# npck3m7k register map
Registers are 8-bit, read-write, no defined reset value unless marked. A register's access mark holds for its fields unless they carry their own. Offsets are from the block's base; [hi:lo] are bit positions; {n}, {i} and the like mark numbered series.

## PM4 — PM4 Module
Base 0x400CF000
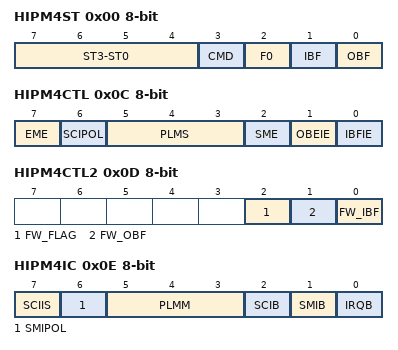
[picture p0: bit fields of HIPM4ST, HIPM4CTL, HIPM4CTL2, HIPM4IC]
0x00 HIPM4ST
  [7:4] ST3-ST0, [3] CMD, [2] F0, [1] IBF, [0] OBF
0x02 HIPM4DO
0x04 HIPM4DI
0x05 SHIPM4DI
0x06 HIPM4DOC
0x08 HIPM4DOM
0x0A HIPM4DIC
0x0C HIPM4CTL
  [7] EME, [6] SCIPOL, [5:3] PLMS, [2] SME, [1] OBEIE, [0] IBFIE
0x0D HIPM4CTL2
  [2] FW_FLAG, [1] FW_OBF, [0] FW_IBF
0x0E HIPM4IC
  [7] SCIIS, [6] SMIPOL, [5:3] PLMM, [2] SCIB, [1] SMIB, [0] IRQB
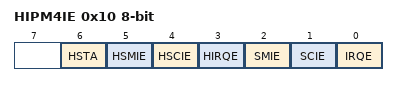
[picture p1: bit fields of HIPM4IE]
0x10 HIPM4IE
  [6] HSTA, [5] HSMIE, [4] HSCIE, [3] HIRQE, [2] SMIE, [1] SCIE, [0] IRQE
0x11 PM4_VER

## SHM — SHM Module
Base 0x40010000
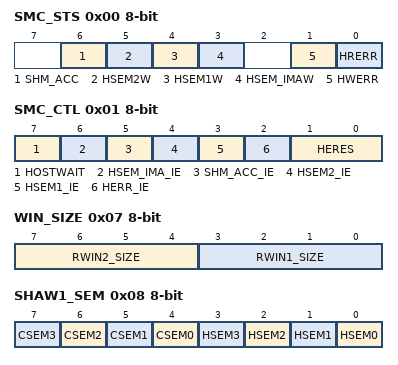
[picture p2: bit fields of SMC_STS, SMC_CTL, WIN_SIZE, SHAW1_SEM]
0x00 SMC_STS
  [6] SHM_ACC, [5] HSEM2W, [4] HSEM1W, [3] HSEM_IMAW, [1] HWERR, [0] HRERR
0x01 SMC_CTL
  [7] HOSTWAIT, [6] HSEM_IMA_IE, [5] SHM_ACC_IE, [4] HSEM2_IE, [3] HSEM1_IE, [2] HERR_IE, [1:0] HERES
0x02 SHM_CTL
  [6] STALL_HOST
0x05 IMA_WIN_SIZE
  [3:0] IMA_SIZE
0x07 WIN_SIZE
  [7:4] RWIN2_SIZE, [3:0] RWIN1_SIZE
0x08 SHAW1_SEM
  [n+4] CSEM{n} (n=0..3), [n] HSEM{n} (n=0..3)
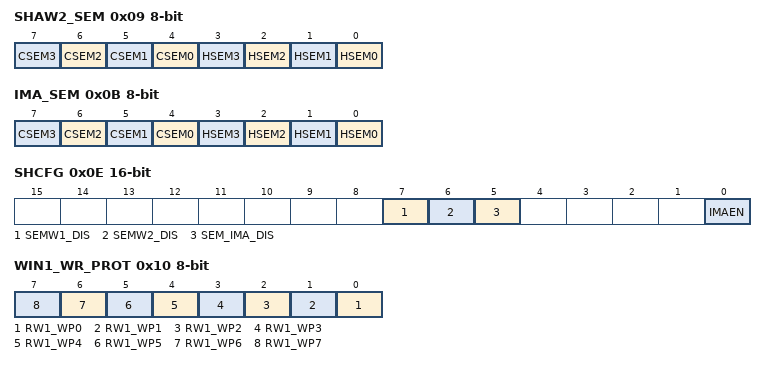
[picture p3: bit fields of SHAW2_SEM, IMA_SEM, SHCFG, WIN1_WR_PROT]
0x09 SHAW2_SEM
  [n+4] CSEM{n} (n=0..3), [n] HSEM{n} (n=0..3)
0x0B IMA_SEM
  [n+4] CSEM{n} (n=0..3), [n] HSEM{n} (n=0..3)
0x0E SHCFG 16-bit
  [7] SEMW1_DIS, [6] SEMW2_DIS, [5] SEM_IMA_DIS, [0] IMAEN
0x10 WIN1_WR_PROT
  [n] RW1_WP{n} (n=0..7)
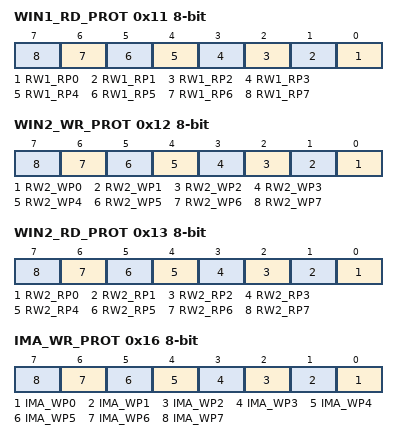
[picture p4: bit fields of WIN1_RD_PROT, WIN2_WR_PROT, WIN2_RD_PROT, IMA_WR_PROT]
0x11 WIN1_RD_PROT
  [n] RW1_RP{n} (n=0..7)
0x12 WIN2_WR_PROT
  [n] RW2_WP{n} (n=0..7)
0x13 WIN2_RD_PROT
  [n] RW2_RP{n} (n=0..7)
0x16 IMA_WR_PROT
  [n] IMA_WP{n} (n=0..7)
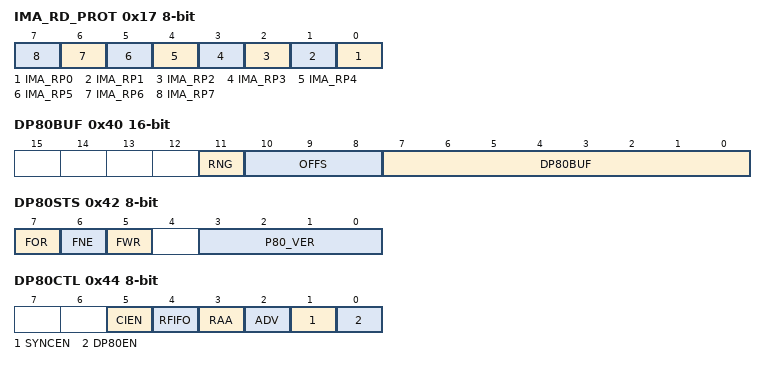
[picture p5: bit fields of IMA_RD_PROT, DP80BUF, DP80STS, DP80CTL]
0x17 IMA_RD_PROT
  [n] IMA_RP{n} (n=0..7)
0x20 WIN_BASE1 32-bit
0x24 WIN_BASE2 32-bit
0x2C IMA_BASE 32-bit
0x3A RST_CFG
  [7] LRESET_PLTRST_DIS
0x40 DP80BUF 16-bit
  [11] RNG, [10:8] OFFS, [7:0] DP80BUF
0x42 DP80STS
  [7] FOR, [6] FNE, [5] FWR, [3:0] P80_VER
0x44 DP80CTL
  [5] CIEN, [4] RFIFO, [3] RAA, [2] ADV, [1] SYNCEN, [0] DP80EN
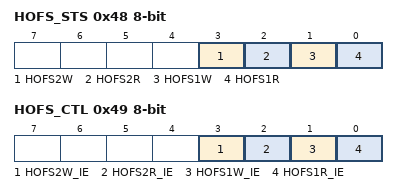
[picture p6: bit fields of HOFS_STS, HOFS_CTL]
0x48 HOFS_STS
  [3] HOFS2W, [2] HOFS2R, [1] HOFS1W, [0] HOFS1R
0x49 HOFS_CTL
  [3] HOFS2W_IE, [2] HOFS2R_IE, [1] HOFS1W_IE, [0] HOFS1R_IE
0x4A COFS2 16-bit
  [11:0] COFS2_DAT
0x4C COFS1 16-bit
  [11:0] COFS1_DAT
0x50 IHOFS2 16-bit
  [11:0] HOFS2_DAT
0x52 IHOFS1 16-bit
  [11:0] HOFS1_DAT
0x7F VERSION

## MSWC — MSWC Module
Base 0x400C1000
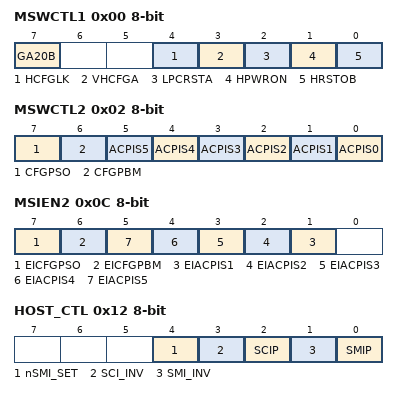
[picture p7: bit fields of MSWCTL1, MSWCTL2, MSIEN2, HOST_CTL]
0x00 MSWCTL1
  [7] GA20B, [4] HCFGLK, [3] VHCFGA, [2] LPCRSTA, [1] HPWRON, [0] HRSTOB
0x02 MSWCTL2
  [7] CFGPSO, [6] CFGPBM, [n] ACPIS{n} (n=0..5)
0x08 HCBAL
  [7:0] HCBA7-0
0x0A HCBAH
  [7:0] HCBA15-0
0x0C MSIEN2
  [7] EICFGPSO, [6] EICFGPBM, [n] EIACPIS{n} (n=1..5)
0x0E MSHES0
  [7] MODIRQ_STS
0x10 MSHEIE0
  [7] MODIRQ_EN
0x12 HOST_CTL
  [4] nSMI_SET, [3] SCI_INV, [2] SCIP, [1] SMI_INV, [0] SMIP
0x14 SMIP_LEN
0x16 SCIP_LEN
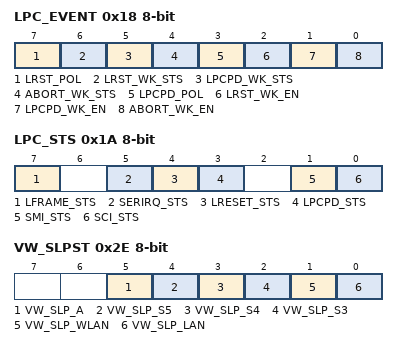
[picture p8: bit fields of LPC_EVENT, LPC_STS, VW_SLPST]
0x18 LPC_EVENT
  [7] LRST_POL, [6] LRST_WK_STS, [5] LPCPD_WK_STS, [4] ABORT_WK_STS, [3] LPCPD_POL, [2] LRST_WK_EN, [1] LPCPD_WK_EN, [0] ABORT_WK_EN
0x1A LPC_STS
  [7] LFRAME_STS, [5] SERIRQ_STS, [4] LRESET_STS, [3] LPCPD_STS, [1] SMI_STS, [0] SCI_STS
0x1C SRID_CR
  [7:0] CHIP_ID_CR
0x1E MSWC_VER
0x20 SID_CR
  [7:0] FAM_ID
0x22 DEVICE_ID_CR
  [4:0] DEV_ID_CR
0x2E VW_SLPST
  [5] VW_SLP_A, [4] VW_SLP_S5, [3] VW_SLP_S4, [2] VW_SLP_S3, [1] VW_SLP_WLAN, [0] VW_SLP_LAN

## MailBox — MailBox Module
Base 0x400A1000
0x00 HOST_TO_EC
0x01 EC_TO_HOST
{0x10+i} GPD_{i} (i=0..47)
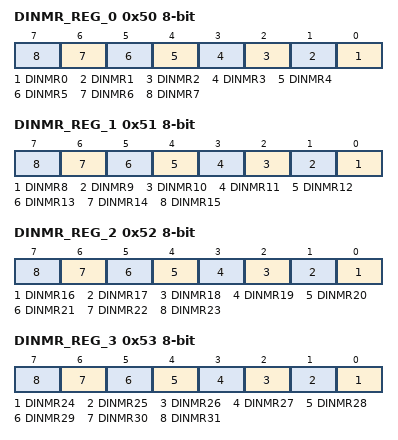
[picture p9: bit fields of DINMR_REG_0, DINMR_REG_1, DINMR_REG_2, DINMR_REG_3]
0x50 DINMR_REG_0
  [n] DINMR{n} (n=0..7)
0x51 DINMR_REG_1
  [n-8] DINMR{n} (n=8..15)
0x52 DINMR_REG_2
  [n-16] DINMR{n} (n=16..23)
0x53 DINMR_REG_3
  [n-24] DINMR{n} (n=24..31)
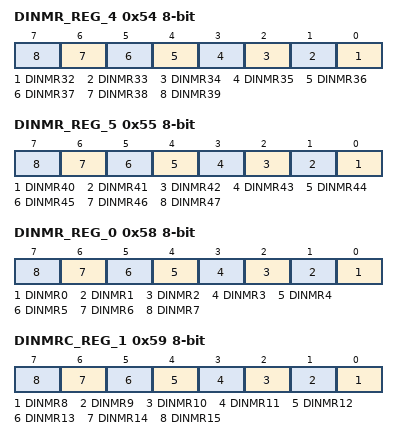
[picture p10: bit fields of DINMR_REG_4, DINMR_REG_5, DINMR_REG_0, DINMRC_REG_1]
0x54 DINMR_REG_4
  [n-32] DINMR{n} (n=32..39)
0x55 DINMR_REG_5
  [n-40] DINMR{n} (n=40..47)
0x58 DINMR_REG_0
  [n] DINMR{n} (n=0..7)
0x59 DINMRC_REG_1
  [n-8] DINMR{n} (n=8..15)
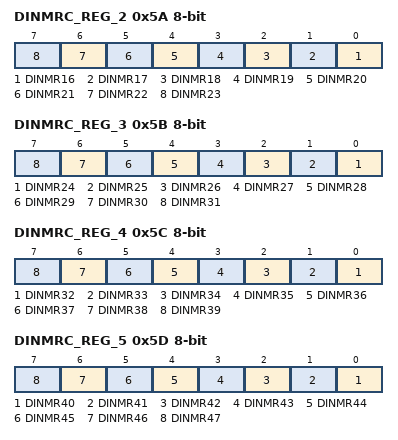
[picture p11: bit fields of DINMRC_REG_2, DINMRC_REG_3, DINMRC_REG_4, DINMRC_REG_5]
0x5A DINMRC_REG_2
  [n-16] DINMR{n} (n=16..23)
0x5B DINMRC_REG_3
  [n-24] DINMR{n} (n=24..31)
0x5C DINMRC_REG_4
  [n-32] DINMR{n} (n=32..39)
0x5D DINMRC_REG_5
  [n-40] DINMR{n} (n=40..47)
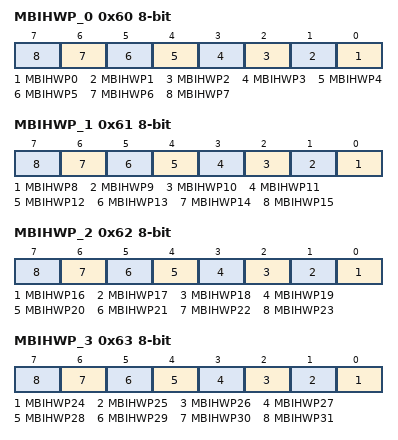
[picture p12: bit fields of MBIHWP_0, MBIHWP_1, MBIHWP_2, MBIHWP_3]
0x60 MBIHWP_0
  [n] MBIHWP{n} (n=0..7)
0x61 MBIHWP_1
  [n-8] MBIHWP{n} (n=8..15)
0x62 MBIHWP_2
  [n-16] MBIHWP{n} (n=16..23)
0x63 MBIHWP_3
  [n-24] MBIHWP{n} (n=24..31)
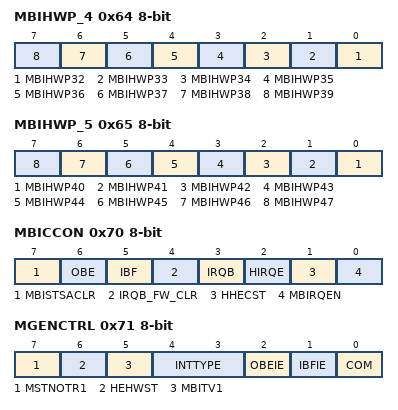
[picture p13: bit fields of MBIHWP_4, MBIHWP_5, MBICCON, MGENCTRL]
0x64 MBIHWP_4
  [n-32] MBIHWP{n} (n=32..39)
0x65 MBIHWP_5
  [n-40] MBIHWP{n} (n=40..47)
0x70 MBICCON
  [7] MBISTSACLR, [6] OBE, [5] IBF, [4] IRQB_FW_CLR, [3] IRQB, [2] HIRQE, [1] HHECST, [0] MBIRQEN
0x71 MGENCTRL
  [7] MSTNOTR1, [6] HEHWST, [5] MBITV1, [4:3] INTTYPE, [2] OBEIE, [1] IBFIE, [0] COM
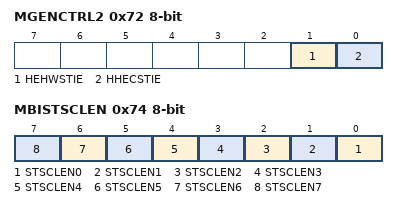
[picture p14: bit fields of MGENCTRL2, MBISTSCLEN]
0x72 MGENCTRL2
  [1] HEHWSTIE, [0] HHECSTIE
0x73 MBISTS
0x74 MBISTSCLEN
  [n] STSCLEN{n} (n=0..7)
